# ATSAM4LS8C device description
Architecture: CORTEX-M4; Family: SAM4; Series: SAM4L
Registers are 32-bit, read-write, reset 0x0 unless marked. A register's access mark holds for its fields unless they carry their own. Offsets are from the block's base; [hi:lo] are bit positions; lines under a group give offsets from that group; {n}, {i} and the like mark numbered series; 'fields as' and 'values as' point back to an identical list.

## PARC — Parallel Capture
Instances: PARC 0x4006C000
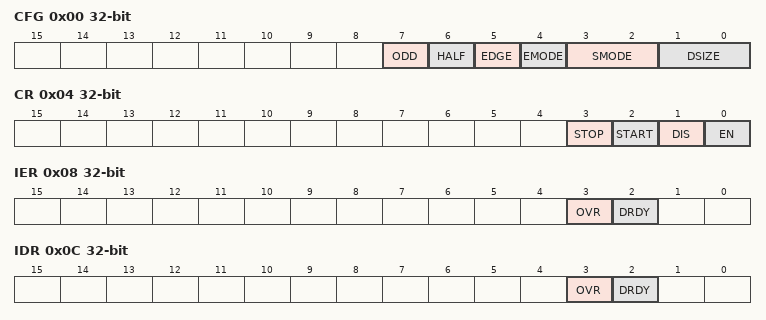
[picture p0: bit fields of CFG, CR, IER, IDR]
0x00 CFG — Configuration Register
  [7] ODD — Odd Capture
  [6] HALF — Half Capture
  [5] EDGE — Sampling Edge Select
  [4] EMODE — Events Mode
  [3:2] SMODE — Sampling Mode
  [1:0] DSIZE — Data Size
0x04 CR — Control Register
  [3] STOP — Stop Capture
  [2] START — Start Capture
  [1] DIS — Disable
  [0] EN — Enable
0x08 IER wo (atomic set of IMR) — Interrupt Enable Register
  [3] OVR — Overrun Interrupt Enable
  [2] DRDY — Data Ready Interrupt Enable
0x0C IDR wo (atomic clear of IMR) — Interrupt Disable Register
  [3] OVR — Overrun Interrupt Disable
  [2] DRDY — Data Ready Interrupt Disable
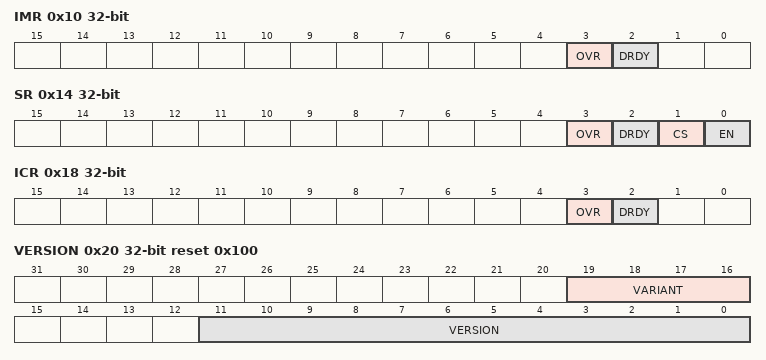
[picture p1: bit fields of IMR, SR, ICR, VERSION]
0x10 IMR ro — Interrupt Mask Register
  [3] OVR — Overrun Interrupt Mask
  [2] DRDY — Data Ready Interrupt Mask
0x14 SR ro — Status Register
  [3] OVR — Overrun Interrupt Status
  [2] DRDY — Data Ready Interrupt Status
  [1] CS — Capture Status
  [0] EN — Enable Status
0x18 ICR wo (atomic clear of SR) — Interrupt Status Clear Register
  [3] OVR — Overrun Interrupt Status Clear
  [2] DRDY — Data Ready Interrupt Status Clear
0x1C RHR ro — Receive Holding Register
  [31:0] CDATA — Captured Data
0x20 VERSION ro reset 0x100
  [19:16] VARIANT — Variant Number
  [11:0] VERSION — Version Number

## PDCA — Peripheral DMA Controller
Instances: PDCA 0x400A2000
{0x0+0x40*i} channel[{i}] (i=0..15) group
  0x00 MAR — Memory Address Register
    [31:0] MADDR — Memory Address
  0x04 PSR reset not defined — Peripheral Select Register
    [7:0] PID — Peripheral Identifier
  0x08 TCR — Transfer Counter Register
    [15:0] TCV — Transfer Counter Value
  0x0C MARR — Memory Address Reload Register
    [31:0] MARV — Memory Address Reload Value
  0x10 TCRR — Transfer Counter Reload Register
    [15:0] TCRV — Transfer Counter Reload Value
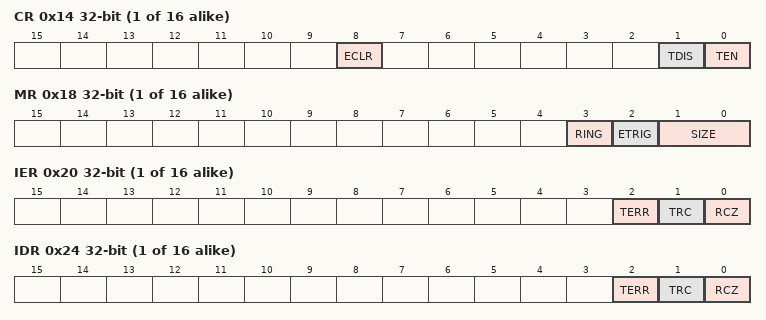
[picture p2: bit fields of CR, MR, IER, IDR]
  0x14 CR wo — Control Register
    [8] ECLR — Error Clear
    [1] TDIS — Transfer Disable
    [0] TEN — Transfer Enable
  0x18 MR — Mode Register
    [3] RING — Ring Buffer
    [2] ETRIG — Event trigger
    [1:0] SIZE — Transfer size
      0=Byte; 1=Half_Word; 2=Word
  0x1C SR ro — Status Register
    [0] TEN — Transfer Enabled
  0x20 IER wo (atomic set of IMR) — Interrupt Enable Register
    [2] TERR — Transfer Error
    [1] TRC — Transfer Complete
    [0] RCZ — Reload Counter Zero
  0x24 IDR wo (atomic clear of IMR) — Interrupt Disable Register
    fields as channel[0].IER
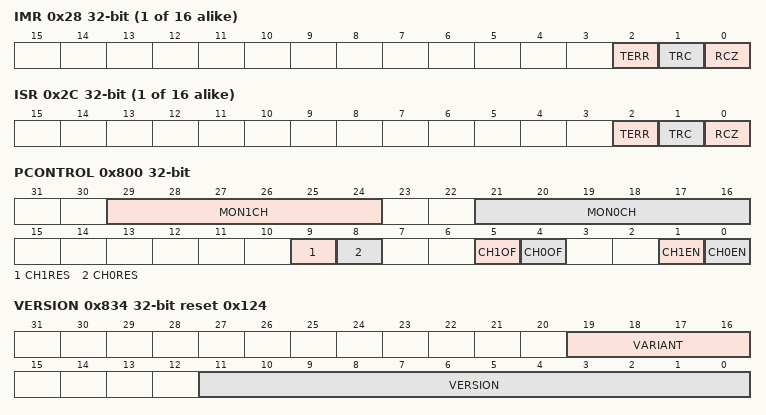
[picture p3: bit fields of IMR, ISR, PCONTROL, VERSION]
  0x28 IMR ro — Interrupt Mask Register
    fields as channel[0].IER
  0x2C ISR ro — Interrupt Status Register
    fields as channel[0].IER
0x800 PCONTROL — Performance Control Register
  [29:24] MON1CH — PDCA Channel to monitor with counter 1
  [21:16] MON0CH — PDCA Channel to monitor with counter 0
  [9] CH1RES — Channel 1 counter reset
  [8] CH0RES — Channel 0 counter reset
  [5] CH1OF — Channel 1 overflow freeze
  [4] CH0OF — Channel 0 Overflow Freeze
  [1] CH1EN — Channel 1 Enabled.
  [0] CH0EN — Channel 0 Enabled
0x804 PRDATA0 ro — Channel 0 Read Data Cycles
  [31:0] DATA — Data Cycles Counted Since Last reset
0x808 PRSTALL0 ro — Channel 0 Read Stall Cycles
  [31:0] STALL — Stall Cycles counted since last reset
0x80C PRLAT0 ro — Channel 0 Read Max Latency
  [15:0] LAT — Maximum Transfer Initiation cycles counted since last reset
0x810 PWDATA0 ro — Channel 0 Write Data Cycles
  [31:0] DATA — Data Cycles Counted since last Reset
0x814 PWSTALL0 ro — Channel 0 Write Stall Cycles
  [31:0] STALL — Stall cycles counted since last reset
0x818 PWLAT0 ro — Channel0 Write Max Latency
  [15:0] LAT — Maximum transfer initiation cycles counted since last reset
0x81C PRDATA1 ro — Channel 1 Read Data Cycles
  [31:0] DATA — Data Cycles Counted Since Last reset
0x820 PRSTALL1 ro — Channel Read Stall Cycles
  [31:0] STALL — Stall Cycles Counted since last reset
0x824 PRLAT1 ro — Channel 1 Read Max Latency
  [15:0] LAT — Maximum Transfer initiation cycles counted since last reset
0x828 PWDATA1 ro — Channel 1 Write Data Cycles
  [31:0] DATA — Data cycles Counted Since last reset
0x82C PWSTALL1 ro — Channel 1 Write stall Cycles
  [31:0] STALL — Stall cycles counted since last reset
0x830 PWLAT1 ro — Channel 1 Read Max Latency
  fields as PWLAT0
0x834 VERSION ro reset 0x124
  [19:16] VARIANT — Variant Number
  [11:0] VERSION — Version Number
